# CY8C5888LTI_LP097 register map
File version: 0.1
CY8C58LP
Registers are 8-bit, read-write, no defined reset value unless marked. A register's access mark holds for its fields unless they carry their own. Offsets are from the block's base; lines under a group give offsets from that group; [hi:lo] are bit positions; {n}, {i} and the like mark numbered series; 'fields as' and 'values as' point back to an identical list; <NAME> marks a mode.

## Memory map
0x00000000 I2C_1
0x00000000 USBUART — USBFS
0x00000000 PSOC — UART
0x00000000 RS232 — UART
0x00000000 RFID — UART
0x00000000 Surtidor — UART
0x00000000 Bluetooth — UART

## PSOC — UART
Base 0x00000000
0x40006527 RX_PSOC_RX_ADDRESS1 — RX Address1 Register
0x40006537 RX_PSOC_RX_ADDRESS2 — RX Address2 Register
0x40006546 TX_PSOC_TX_DATA — TX Data Register
0x40006547 RX_PSOC_RX_DATA — RX Data Register
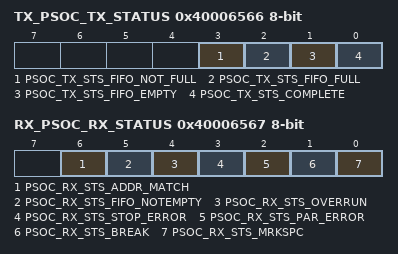
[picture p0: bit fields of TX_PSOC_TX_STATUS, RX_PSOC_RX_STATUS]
0x40006566 TX_PSOC_TX_STATUS — TX status register
  [3] PSOC_TX_STS_FIFO_NOT_FULL ro, [2] PSOC_TX_STS_FIFO_FULL ro, [1] PSOC_TX_STS_FIFO_EMPTY ro, [0] PSOC_TX_STS_COMPLETE ro
0x40006567 RX_PSOC_RX_STATUS — RX status register
  [6] PSOC_RX_STS_ADDR_MATCH ro, [5] PSOC_RX_STS_FIFO_NOTEMPTY ro, [4] PSOC_RX_STS_OVERRUN ro, [3] PSOC_RX_STS_STOP_ERROR ro, [2] PSOC_RX_STS_PAR_ERROR ro, [1] PSOC_RX_STS_BREAK ro, [0] PSOC_RX_STS_MRKSPC ro

## RS232 — UART
Base 0x00000000
0x40006429 RX_RS232_RX_ADDRESS1 — RX Address1 Register
0x40006439 RX_RS232_RX_ADDRESS2 — RX Address2 Register
0x40006447 TX_RS232_TX_DATA — TX Data Register
0x40006449 RX_RS232_RX_DATA — RX Data Register
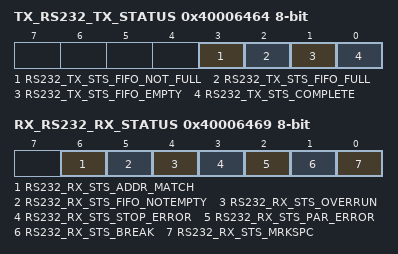
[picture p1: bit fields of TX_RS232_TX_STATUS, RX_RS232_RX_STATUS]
0x40006464 TX_RS232_TX_STATUS — TX status register
  [3] RS232_TX_STS_FIFO_NOT_FULL ro, [2] RS232_TX_STS_FIFO_FULL ro, [1] RS232_TX_STS_FIFO_EMPTY ro, [0] RS232_TX_STS_COMPLETE ro
0x40006469 RX_RS232_RX_STATUS — RX status register
  [6] RS232_RX_STS_ADDR_MATCH ro, [5] RS232_RX_STS_FIFO_NOTEMPTY ro, [4] RS232_RX_STS_OVERRUN ro, [3] RS232_RX_STS_STOP_ERROR ro, [2] RS232_RX_STS_PAR_ERROR ro, [1] RS232_RX_STS_BREAK ro, [0] RS232_RX_STS_MRKSPC ro

## RFID — UART
Base 0x00000000
0x40006423 RX_RFID_RX_ADDRESS1 — RX Address1 Register
0x40006433 RX_RFID_RX_ADDRESS2 — RX Address2 Register
0x40006443 RX_RFID_RX_DATA — RX Data Register
0x40006444 TX_RFID_TX_DATA — TX Data Register
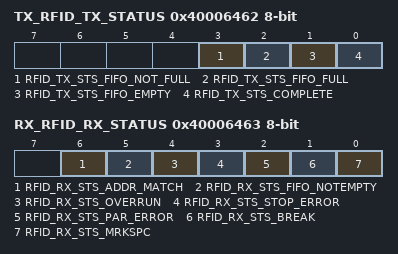
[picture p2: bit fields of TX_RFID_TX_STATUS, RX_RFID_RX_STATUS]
0x40006462 TX_RFID_TX_STATUS — TX status register
  [3] RFID_TX_STS_FIFO_NOT_FULL ro, [2] RFID_TX_STS_FIFO_FULL ro, [1] RFID_TX_STS_FIFO_EMPTY ro, [0] RFID_TX_STS_COMPLETE ro
0x40006463 RX_RFID_RX_STATUS — RX status register
  [6] RFID_RX_STS_ADDR_MATCH ro, [5] RFID_RX_STS_FIFO_NOTEMPTY ro, [4] RFID_RX_STS_OVERRUN ro, [3] RFID_RX_STS_STOP_ERROR ro, [2] RFID_RX_STS_PAR_ERROR ro, [1] RFID_RX_STS_BREAK ro, [0] RFID_RX_STS_MRKSPC ro

## Surtidor — UART
Base 0x00000000
0x4000642A RX_Surtidor_RX_ADDRESS1 — RX Address1 Register
0x4000643A RX_Surtidor_RX_ADDRESS2 — RX Address2 Register
0x4000644A RX_Surtidor_RX_DATA — RX Data Register
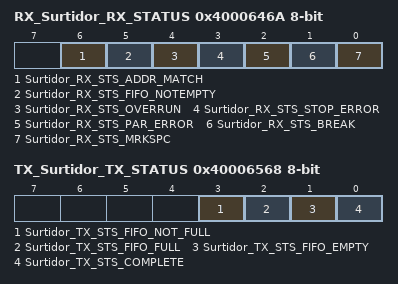
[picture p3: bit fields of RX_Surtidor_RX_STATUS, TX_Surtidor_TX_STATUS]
0x4000646A RX_Surtidor_RX_STATUS — RX status register
  [6] Surtidor_RX_STS_ADDR_MATCH ro, [5] Surtidor_RX_STS_FIFO_NOTEMPTY ro, [4] Surtidor_RX_STS_OVERRUN ro, [3] Surtidor_RX_STS_STOP_ERROR ro, [2] Surtidor_RX_STS_PAR_ERROR ro, [1] Surtidor_RX_STS_BREAK ro, [0] Surtidor_RX_STS_MRKSPC ro
0x40006548 TX_Surtidor_TX_DATA — TX Data Register
0x40006568 TX_Surtidor_TX_STATUS — TX status register
  [3] Surtidor_TX_STS_FIFO_NOT_FULL ro, [2] Surtidor_TX_STS_FIFO_FULL ro, [1] Surtidor_TX_STS_FIFO_EMPTY ro, [0] Surtidor_TX_STS_COMPLETE ro

## Bluetooth — UART
Base 0x00000000
0x4000644C TX_Bluetooth_TX_DATA — TX Data Register
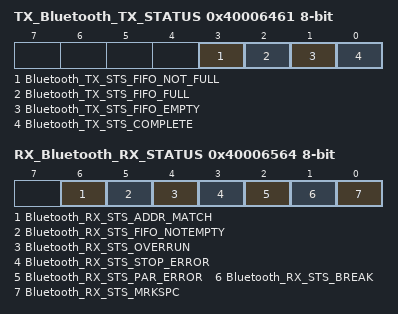
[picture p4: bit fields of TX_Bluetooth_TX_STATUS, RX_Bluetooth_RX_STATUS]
0x40006461 TX_Bluetooth_TX_STATUS — TX status register
  [3] Bluetooth_TX_STS_FIFO_NOT_FULL ro, [2] Bluetooth_TX_STS_FIFO_FULL ro, [1] Bluetooth_TX_STS_FIFO_EMPTY ro, [0] Bluetooth_TX_STS_COMPLETE ro
0x4000652B RX_Bluetooth_RX_ADDRESS1 — RX Address1 Register
0x4000653B RX_Bluetooth_RX_ADDRESS2 — RX Address2 Register
0x4000654B RX_Bluetooth_RX_DATA — RX Data Register
0x40006564 RX_Bluetooth_RX_STATUS — RX status register
  [6] Bluetooth_RX_STS_ADDR_MATCH ro, [5] Bluetooth_RX_STS_FIFO_NOTEMPTY ro, [4] Bluetooth_RX_STS_OVERRUN ro, [3] Bluetooth_RX_STS_STOP_ERROR ro, [2] Bluetooth_RX_STS_PAR_ERROR ro, [1] Bluetooth_RX_STS_BREAK ro, [0] Bluetooth_RX_STS_MRKSPC ro
